VERSION ""

NS_ :

BS_:

BU_:

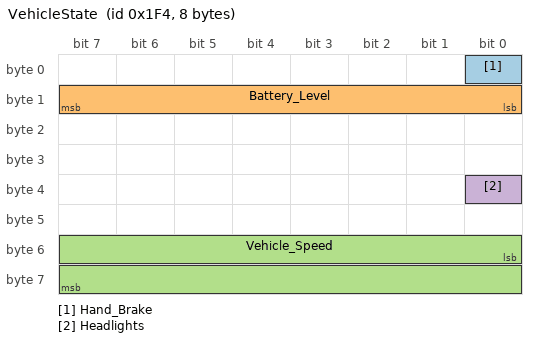
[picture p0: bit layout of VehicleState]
BO_ 500 VehicleState: 8 Vector__XXX
 SG_ Hand_Brake : 0|1@1+ (1,0) [0|1] "" Vector__XXX
 SG_ Battery_Level : 8|8@1+ (1,0) [0|100] "%" Vector__XXX
 SG_ Vehicle_Speed : 48|16@1+ (1,0) [0|250] "km/h" Vector__XXX
 SG_ Headlights : 32|1@1+ (1,0) [0|1] "" Vector__XXX
